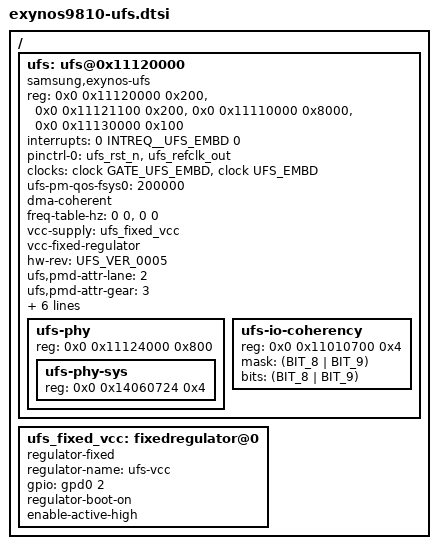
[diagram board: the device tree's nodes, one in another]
/*
 * SAMSUNG EXYNOS9810 SoC device tree source
 *
 * Copyright (c) 2017 Samsung Electronics Co., Ltd.
 *		http://www.samsung.com
 *
 * SAMSUNG EXYNOS9810 SoC device nodes are listed in this file.
 * EXYNOS9810 based board files can include this file and provide
 * values for board specfic bindings.
 *
 * This program is free software; you can redistribute it and/or modify
 * it under the terms of the GNU General Public License version 2 as
 * published by the Free Software Foundation.
 */

/ {
	ufs: ufs@0x11120000 {
		/* ----------------------- */
		/* 1. SYSTEM CONFIGURATION */
		/* ----------------------- */
		compatible ="samsung,exynos-ufs";
		#address-cells = <2>;
		#size-cells = <1>;
		ranges;

		reg =
			<0x0 0x11120000 0x200>,	/* 0: HCI standard */
			<0x0 0x11121100 0x200>,	/* 1: Vendor specificed */
			<0x0 0x11110000 0x8000>,	/* 2: UNIPRO */
			<0x0 0x11130000 0x100>;	/* 3: UFS protector */
		interrupts = <0 INTREQ__UFS_EMBD 0>;
		pinctrl-names = "default";
		pinctrl-0 = <&ufs_rst_n &ufs_refclk_out>;
		clocks =
			/* aclk clock */
			<&clock GATE_UFS_EMBD>,
			/* unipro clocks */
			<&clock UFS_EMBD>;

		clock-names =
			/* aclk clocks */
			"GATE_UFS_EMBD",
			/* unipro clocks */
			"UFS_EMBD";

		/* PM QoS for INT power domain */
/*		ufs-pm-qos-int = <400000>;*/

		/* PM QoS for FSYS0 power domain */
		ufs-pm-qos-fsys0 = <200000>;

		/* DMA coherent callback, should be coupled with 'ufs-sys' */
		dma-coherent;

		/* ----------------------- */
		/* 2. UFS COMMON           */
		/* ----------------------- */
		freq-table-hz = <0 0>, <0 0>;

		vcc-supply = <&ufs_fixed_vcc>;
		vcc-fixed-regulator;


		/* ----------------------- */
		/* 3. UFS EXYNOS           */
		/* ----------------------- */
		hw-rev = <UFS_VER_0005>;

		/* power mode change */
		ufs,pmd-attr-lane = /bits/ 8 <2>;
		ufs,pmd-attr-gear = /bits/ 8 <3>;

		/* hiberantion */
		ufs-rx-min-activate-time-cap = <3>;
		ufs-rx-hibern8-time-cap = <2>;
		ufs-tx-hibern8-time-cap = <2>;

		/* board type for UFS CAL */
		brd-for-cal = <0>;

		fmp-id = <0>;
		smu-id = <0>;

		/* ----------------------- */
		/* 4. ADDITIONAL NODES     */
		/* ----------------------- */
		/* PHY isolation */
		ufs-phy {
			#address-cells = <2>;
			#size-cells = <1>;
			ranges;
			reg = <0x0 0x11124000 0x800>;

			ufs-phy-sys {
				reg = <0x0 0x14060724 0x4>;
			};
		};

		/* SYSREG */
		ufs-io-coherency {
			#address-cells = <2>;
			#size-cells = <1>;
			ranges;

			reg =
				<0x0 0x11010700 0x4>;

			mask = <(BIT_8 | BIT_9)>;
			bits = <(BIT_8 | BIT_9)>;
		};

	};

	ufs_fixed_vcc: fixedregulator@0 {
		       compatible = "regulator-fixed";
		       regulator-name = "ufs-vcc";
		       gpio = <&gpd0 2 0>;
		       regulator-boot-on;
		       enable-active-high;
		};
	};
